# SWM050 register map
File version: 0.1
SWM050 Microcontroller registers
Registers are 32-bit, read-write, reset 0x0 unless marked. A register's access mark holds for its fields unless they carry their own. Offsets are from the block's base; lines under a group give offsets from that group; [hi:lo] are bit positions; {n}, {i} and the like mark numbered series; 'fields as' and 'values as' point back to an identical list; <NAME> marks a mode.

## Memory map
0x40000030 PORT size 0x800 — Registers group
0x40000800 ACMP size 0x800 — Registers group
0x40001000 GPIOA size 0x800 — Registers group
0x40001030 EXTIA size 0x800 — Registers group
0x40001050 GPIO_EXTA size 0x800 — Registers group
0x40002000 TMRSE0 size 0x800 — Registers group
0x40002400 TMRSE1 size 0x800 — Registers group
0x40019000 WDT size 0x800 — Registers group
0x400F0000 SYS size 0x800 — Registers group

## SYS — Registers group
Base 0x400F0000
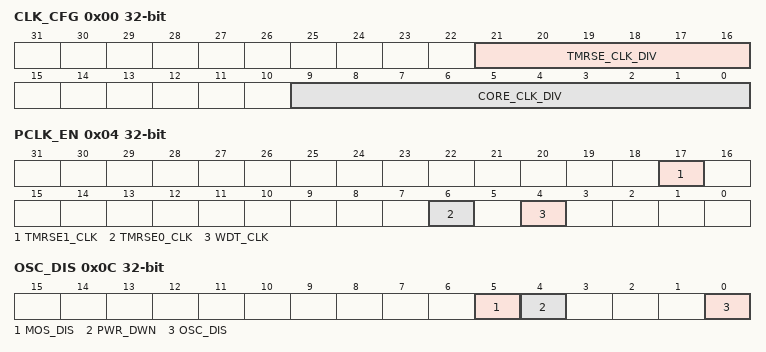
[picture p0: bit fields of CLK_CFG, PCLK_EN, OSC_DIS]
0x00 CLK_CFG
  [21:16] TMRSE_CLK_DIV — =0：2分频 =奇数：不分频 =偶数 分频，直接对时钟源分频，不依赖于内核时钟
  [9:0] CORE_CLK_DIV — =0：2分频 =奇数：不分频 =偶数 分频
0x04 PCLK_EN
  [17] TMRSE1_CLK, [6] TMRSE0_CLK, [4] WDT_CLK
0x08 DBL_IRC
  [0] DBL_IRC — 0 18MHz 1 36MHz
0x0C OSC_DIS
  [5] MOS_DIS
  [4] PWR_DWN — 1 Power-down
  [0] OSC_DIS

## PORT — Registers group
Base 0x40000030
0x00 SWD_SEL
  [0] EN — 0 A1/A2功能由PORT_SEL决定 1 A1/A2连接到SWD功能，分别为SWDIO/SWCLK功能
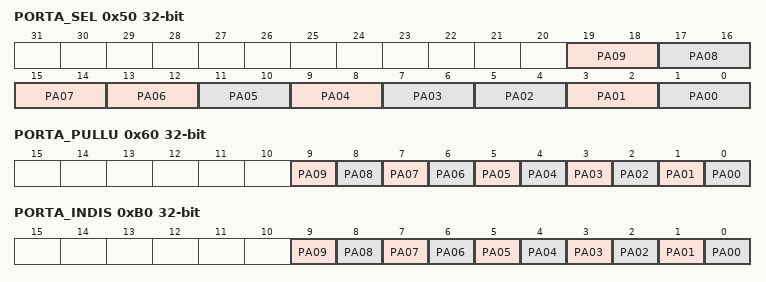
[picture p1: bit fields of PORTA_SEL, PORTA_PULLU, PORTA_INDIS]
0x50 PORTA_SEL
  [19:18] PA09 — 00 GPIO 01 10/11
  [17:16] PA08 — 00 GPIO 01 10/11
  [15:14] PA07 — 00 GPIO 01 TMRSE1OUT 10/11
  [2n+1:2n] PA{n:02} (n=3..6) — 00 GPIO 01 10/11
  [5:4] PA02 — 00 GPIO 01 TMRSE1_IN 10/11
  [3:2] PA01 — 00 GPIO 01 TMRSE0_OUT 10/11
  [1:0] PA00 — 00 GPIO 01 TMRSE0_IN 10/11
0x60 PORTA_PULLU
  [n] PA{n:02} (n=1..9)
  [0] PA00 — 0 上拉关闭 1 上拉开启
0xB0 PORTA_INDIS
  [n] PA{n:02} (n=1..9)
  [0] PA00 — 0 GPIOA.0输入功能不禁止 1 GPIOA.0输入功能禁止，以降低功耗

## GPIOA — Registers group
Base 0x40001000
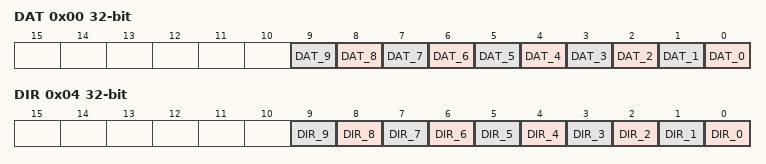
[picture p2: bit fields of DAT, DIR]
0x00 DAT
  [n] DAT_{n} (n=0..9)
0x04 DIR
  [n] DIR_{n} (n=0..9)

## GPIO_EXTA — Registers group
Base 0x40001050
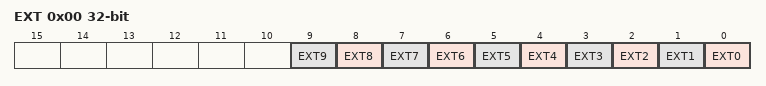
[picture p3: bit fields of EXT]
0x00 EXT ro
  [n] EXT{n} rw (n=0..9)

## ACMP — Registers group
Base 0x40000800
0x00 CPEN
  [4] EN
0x04 CPLEVEL
  [7:0] LEVEL
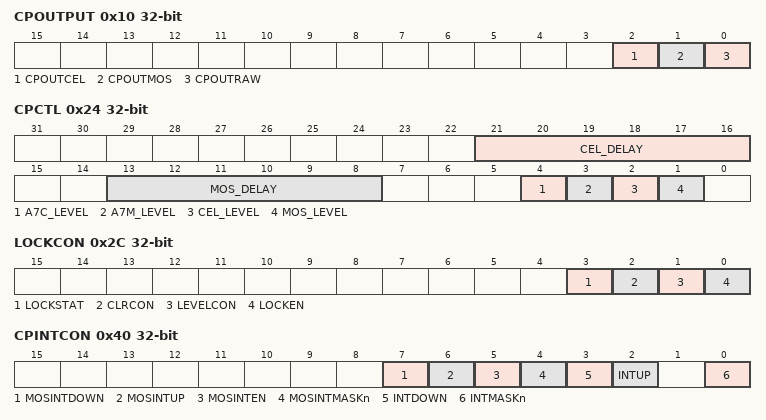
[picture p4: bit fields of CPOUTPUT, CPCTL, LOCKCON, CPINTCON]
0x10 CPOUTPUT
  [2] CPOUTCEL, [1] CPOUTMOS, [0] CPOUTRAW
0x20 CPMOD
  [0] WORKSMOD
0x24 CPCTL
  [21:16] CEL_DELAY, [13:8] MOS_DELAY, [4] A7C_LEVEL, [3] A7M_LEVEL, [2] CEL_LEVEL, [1] MOS_LEVEL
0x28 CLRLOCK
  [0] CLR
0x2C LOCKCON
  [3] LOCKSTAT, [2] CLRCON, [1] LEVELCON, [0] LOCKEN
0x40 CPINTCON
  [7] MOSINTDOWN, [6] MOSINTUP, [5] MOSINTEN, [4] MOSINTMASKn, [3] INTDOWN, [2] INTUP, [0] INTMASKn
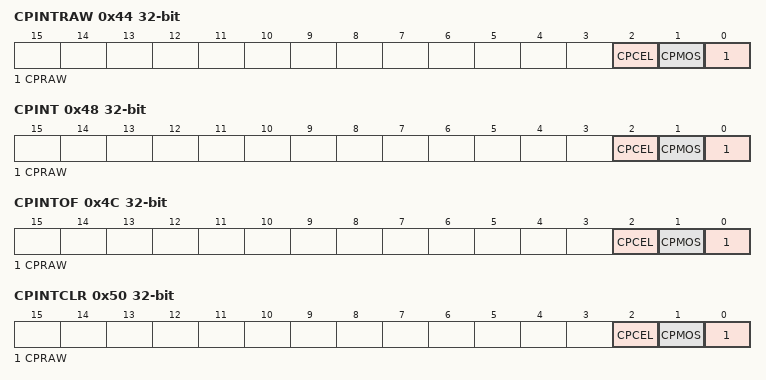
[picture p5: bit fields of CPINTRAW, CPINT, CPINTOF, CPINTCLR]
0x44 CPINTRAW
  [2] CPCEL, [1] CPMOS, [0] CPRAW
0x48 CPINT
  [2] CPCEL, [1] CPMOS, [0] CPRAW
0x4C CPINTOF
  [2] CPCEL, [1] CPMOS, [0] CPRAW
0x50 CPINTCLR
  [2] CPCEL, [1] CPMOS, [0] CPRAW

## EXTIA — Registers group
Base 0x40001030
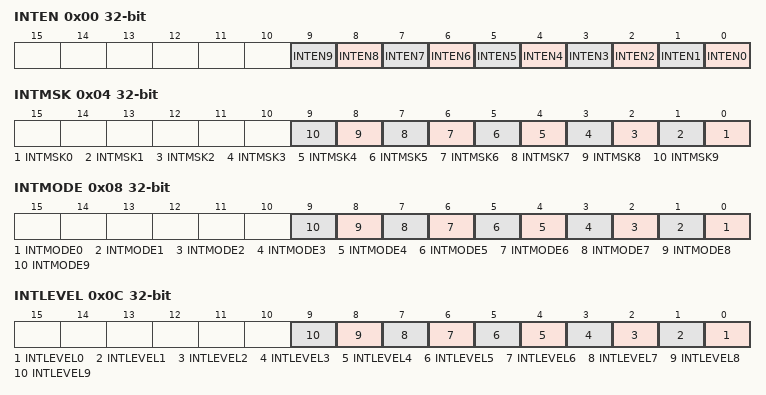
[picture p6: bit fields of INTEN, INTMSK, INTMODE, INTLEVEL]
0x00 INTEN
  [n] INTEN{n} (n=0..9)
0x04 INTMSK
  [n] INTMSK{n} (n=0..9)
0x08 INTMODE
  [n] INTMODE{n} (n=0..9)
0x0C INTLEVEL
  [n] INTLEVEL{n} (n=0..9)
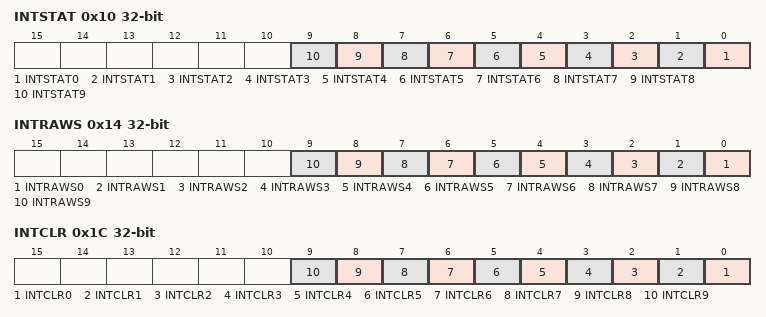
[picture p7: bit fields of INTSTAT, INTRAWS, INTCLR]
0x10 INTSTAT ro
  [n] INTSTAT{n} rw (n=0..9)
0x14 INTRAWS ro
  [n] INTRAWS{n} rw (n=0..9)
0x1C INTCLR
  [n] INTCLR{n} (n=0..9)

## WDT — Registers group
Base 0x40019000
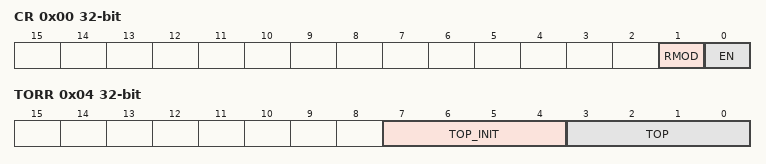
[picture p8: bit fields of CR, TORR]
0x00 CR
  [1] RMOD — 0 超时即复位 1 第一次超时产生中断，若产生第二次超时时，没有清除中断，则系统复位
  [0] EN
0x04 TORR
  [7:4] TOP_INIT — 超时后将要填装的值
  [3:0] TOP — 初始值（在WDT使能之前写入值） 2^(8+TOP)，即24位
0x08 CCVR ro
0x0C CRR ro
0x10 STAT ro
0x14 ICLR ro

## TMRSE0 — Registers group
Base 0x40002000
Same registers: TMRSE1 0x40002400
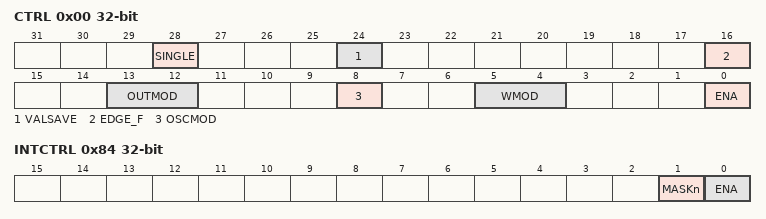
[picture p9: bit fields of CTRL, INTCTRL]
0x00 CTRL
  [28] SINGLE — 1 单次模式 0 循环模式
  [24] VALSAVE — 保留计数值
  [16] EDGE_F — 0 上升沿 1 下降沿
  [13:12] OUTMOD — 00 无输出 01 取反 10 置高 11 置低
  [8] OSCMOD — 0 内部 1 外部
  [5:4] WMOD — 00 定时器/计数器模式 01 PWM模式 10 脉宽捕捉模式 11 占空比捕捉模式
  [0] ENA — 模块使能
0x04 TARVAL
0x08 CURVAL
0x0C CAPVAL
0x10 CAPHALF
0x14 STATE_P
0x80 OUT_LVL
0x84 INTCTRL
  [1] MASKn — 0 屏蔽
  [0] ENA — 1 使能 to observe sate, you should set this bit 1
0x88 INTRSTAT
0x8C INTSTAT
0x90 INTOFLAG
